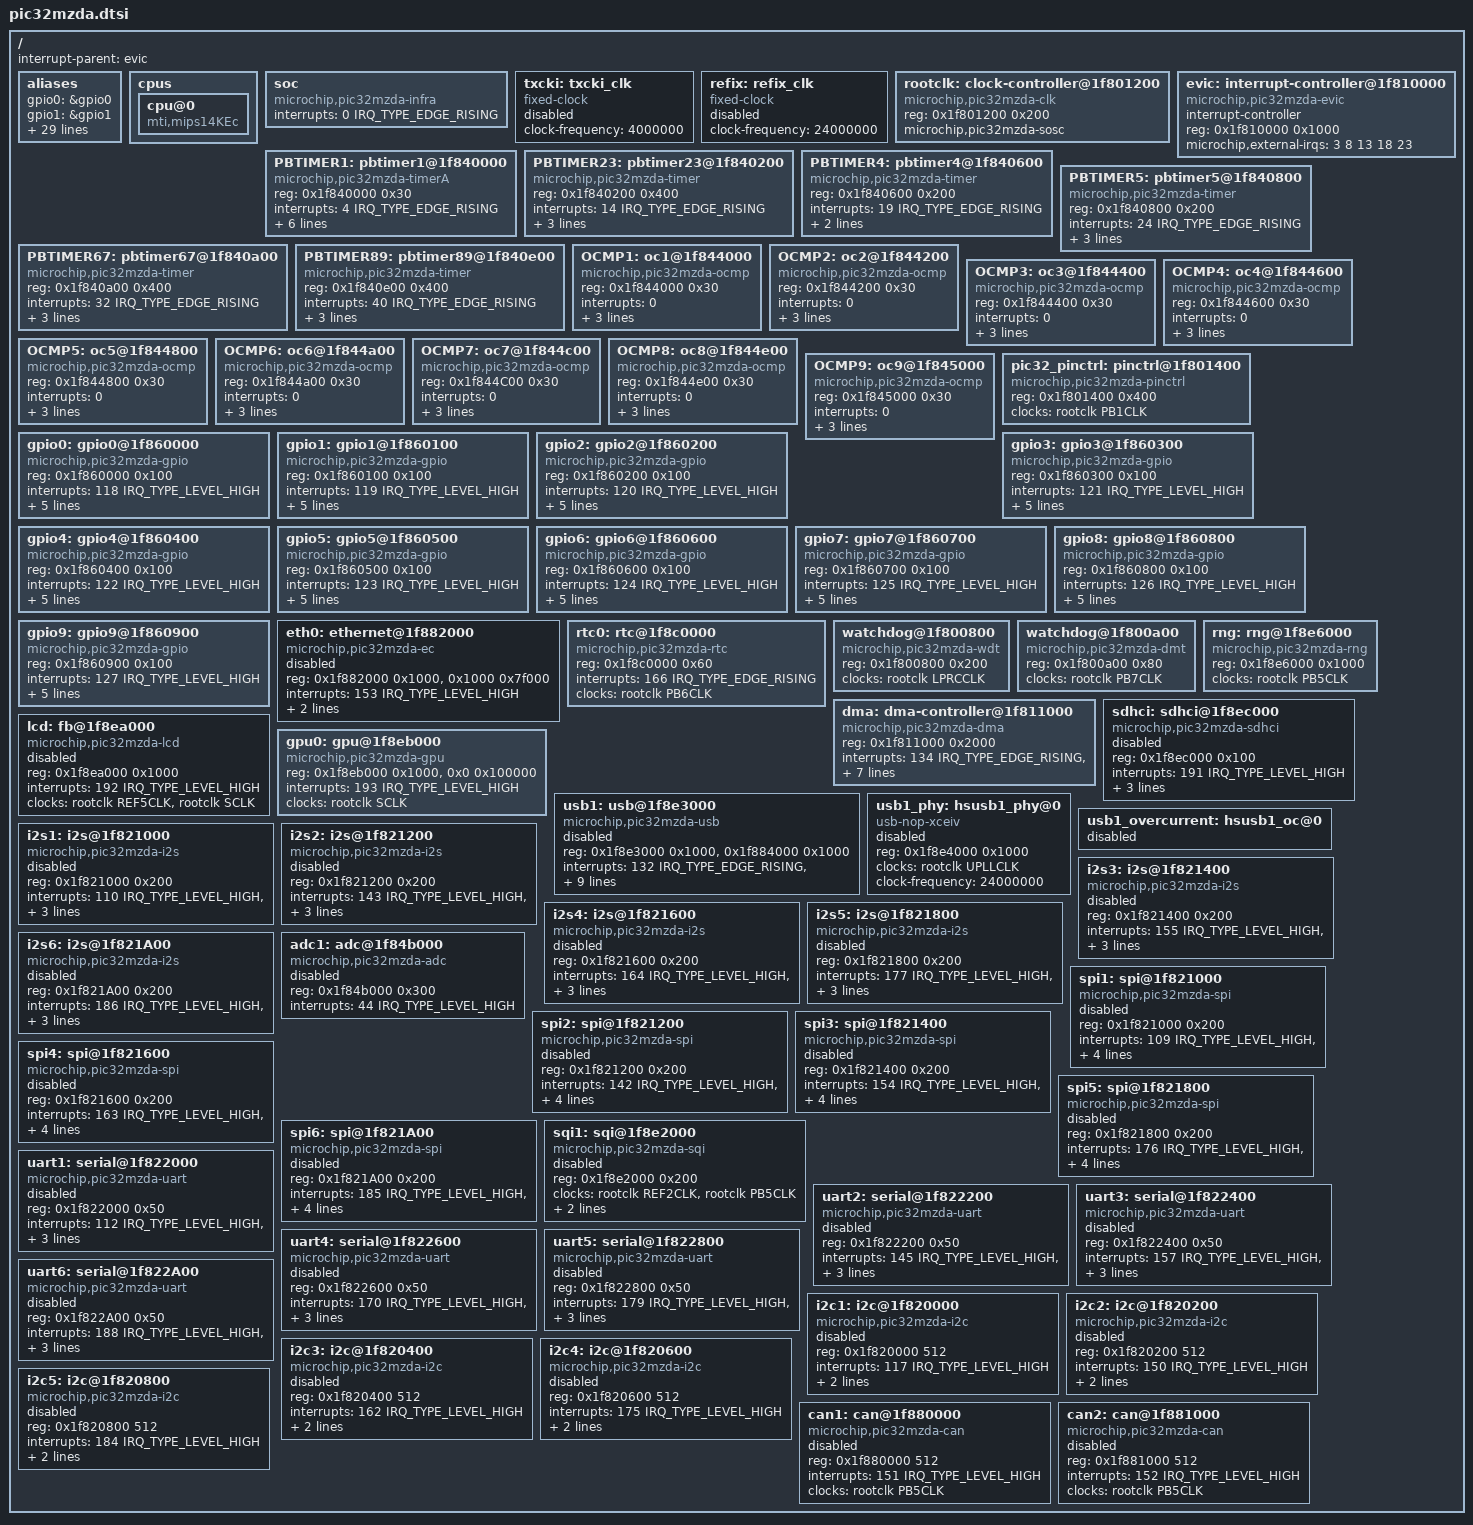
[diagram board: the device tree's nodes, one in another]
/*
 * Copyright (C) 2015 Microchip Technology Inc.  All rights reserved.
 *
 * This program is free software; you can redistribute it and/or modify
 * it under the terms of the GNU General Public License version 2 as
 * published by the Free Software Foundation.
 *
 */
#include <dt-bindings/clock/microchip,pic32-clock.h>
#include <dt-bindings/interrupt-controller/irq.h>

/ {
	#address-cells = <1>;
	#size-cells = <1>;
	interrupt-parent = <&evic>;

	aliases {
		gpio0 = &gpio0;
		gpio1 = &gpio1;
		gpio2 = &gpio2;
		gpio3 = &gpio3;
		gpio4 = &gpio4;
		gpio5 = &gpio5;
		gpio6 = &gpio6;
		gpio7 = &gpio7;
		gpio8 = &gpio8;
		gpio9 = &gpio9;
		serial0 = &uart1;
		serial1 = &uart2;
		serial2 = &uart3;
		serial3 = &uart4;
		serial4 = &uart5;
		serial5 = &uart6;
		i2s1 = &i2s1;
		i2s2 = &i2s2;
		i2s3 = &i2s3;
		i2s4 = &i2s4;
		i2s5 = &i2s5;
		i2s6 = &i2s6;
		spi1 = &spi1;
		spi2 = &spi2;
		spi3 = &spi3;
		spi4 = &spi4;
		spi5 = &spi5;
		spi6 = &spi6;
		spi7 = &sqi1;
		usb1 = &usb1;
		usb1_phy = &usb1_phy;
	};

	cpus {
		#address-cells = <1>;
		#size-cells = <0>;

		cpu@0 {
			compatible = "mti,mips14KEc";
			device_type = "cpu";
		};
	};

	soc {
		compatible = "microchip,pic32mzda-infra";
		interrupts = <0 IRQ_TYPE_EDGE_RISING>;
	};

	/* external clock input on TxCLKI pin */
	txcki: txcki_clk {
		#clock-cells = <0>;
		compatible = "fixed-clock";
		clock-frequency = <4000000>;
		status = "disabled";
	};

	/* external input on REFCLKIx pin */
	refix: refix_clk {
		#clock-cells = <0>;
		compatible = "fixed-clock";
		clock-frequency = <24000000>;
		status = "disabled";
	};

	rootclk: clock-controller@1f801200 {
		compatible = "microchip,pic32mzda-clk";
		reg = <0x1f801200 0x200>;
		#clock-cells = <1>;
		microchip,pic32mzda-sosc;
	};

	evic: interrupt-controller@1f810000 {
		compatible = "microchip,pic32mzda-evic";
		interrupt-controller;
		#interrupt-cells = <2>;
		reg = <0x1f810000 0x1000>;
		microchip,external-irqs = <3 8 13 18 23>;
	};

	/* 16-bit class-a timer */
	PBTIMER1: pbtimer1@1f840000 {
		#timer-cells = <0>;
		reg = <0x1f840000 0x30>;
		compatible = "microchip,pic32mzda-timerA";
		interrupts = <4 IRQ_TYPE_EDGE_RISING>;
		clocks = <&rootclk PB3CLK>, <&rootclk SOSCCLK>, <&rootclk LPRCCLK>;
		microchip,clock-indices = <0>, <1>, <5>;
		timer-id = <1>;
		microchip,timer-class-A;  /* class A timer */
		microchip,timer-version = <2>; /* v2 timer */
	};

	/* 32-bit class-b timer */
	PBTIMER23: pbtimer23@1f840200 {
		#timer-cells = <0>;
		compatible = "microchip,pic32mzda-timer";
		reg = <0x1f840200 0x400>;
		interrupts = <14 IRQ_TYPE_EDGE_RISING>;
		clocks = <&rootclk PB3CLK>, <&txcki>;
		timer-id = <2>;
		microchip,timer-32bit;	 /* class B, 32-bit combined timer */
	};

	/* 16-bit class-b timer */
	PBTIMER4: pbtimer4@1f840600 {
		#timer-cells = <0>;
		compatible = "microchip,pic32mzda-timer";
		reg = <0x1f840600 0x200>;
		interrupts = <19 IRQ_TYPE_EDGE_RISING>;
		clocks = <&rootclk PB3CLK>, <&txcki>;
		timer-id = <4>;
	};

	/* 16-bit class-b timer */
	PBTIMER5: pbtimer5@1f840800 {
		#timer-cells = <0>;
		compatible = "microchip,pic32mzda-timer";
		reg = <0x1f840800 0x200>;
		interrupts = <24 IRQ_TYPE_EDGE_RISING>;
		clocks = <&rootclk PB3CLK>, <&txcki>;
		timer-id = <5>;
		microchip,timer-adc; /* can trigger ADC on match */
	};

	/* 32-bit class-b timer */
	PBTIMER67: pbtimer67@1f840a00 {
		#timer-cells = <0>;
		compatible = "microchip,pic32mzda-timer";
		reg = <0x1f840a00 0x400>;
		interrupts = <32 IRQ_TYPE_EDGE_RISING>;
		clocks = <&rootclk PB3CLK>, <&txcki>;
		timer-id = <6>;
		microchip,timer-32bit;
	};

	/* 32-bit class-b timer */
	PBTIMER89: pbtimer89@1f840e00 {
		#timer-cells = <0>;
		compatible = "microchip,pic32mzda-timer";
		reg = <0x1f840e00 0x400>;
		interrupts = <40 IRQ_TYPE_EDGE_RISING>;
		clocks = <&rootclk PB3CLK>, <&txcki>;
		timer-id = <8>;
		microchip,timer-32bit;
	};

	/* 32-bit time-base and 32-bit compare */
	OCMP1: oc1@1f844000 {
		#oc-cells = <0>;
		compatible = "microchip,pic32mzda-ocmp";
		reg = <0x1f844000 0x30>;
		interrupts = <0>;
		oc-id = <1>;
		microchip,oc-32bit;
		microchip,oc-adc;
	};

	/* 16-bit time-base, hence 16-bit count comparision */
	OCMP2: oc2@1f844200 {
		#oc-cells = <0>;
		compatible = "microchip,pic32mzda-ocmp";
		reg = <0x1f844200 0x30>;
		interrupts = <0>;
		oc-id = <2>;
		microchip,oc-adc;
		microchip,oc-32bit;
	};

	OCMP3: oc3@1f844400 {
		#oc-cells = <0>;
		compatible = "microchip,pic32mzda-ocmp";
		reg = <0x1f844400 0x30>;
		interrupts = <0>;
		oc-id = <3>;
		microchip,oc-adc;
		microchip,oc-32bit;
	};

	OCMP4: oc4@1f844600 {
		#oc-cells = <0>;
		compatible = "microchip,pic32mzda-ocmp";
		reg = <0x1f844600 0x30>;
		interrupts = <0>;
		oc-id = <4>;
		microchip,oc-adc;
		microchip,oc-32bit;
	};

	OCMP5: oc5@1f844800 {
		#oc-cells = <0>;
		compatible = "microchip,pic32mzda-ocmp";
		reg = <0x1f844800 0x30>;
		interrupts = <0>;
		oc-id = <5>;
		microchip,oc-adc;
		microchip,oc-32bit;
	};

	OCMP6: oc6@1f844a00 {
		#oc-cells = <0>;
		compatible = "microchip,pic32mzda-ocmp";
		reg = <0x1f844a00 0x30>;
		interrupts = <0>;
		oc-id = <2>;
		microchip,oc-adc;
		microchip,oc-32bit;
	};

	OCMP7: oc7@1f844c00 {
		#oc-cells = <0>;
		compatible = "microchip,pic32mzda-ocmp";
		reg = <0x1f844C00 0x30>;
		interrupts = <0>;
		oc-id = <7>;
		microchip,oc-adc;
		microchip,oc-32bit;
	};

	OCMP8: oc8@1f844e00 {
		#oc-cells = <0>;
		compatible = "microchip,pic32mzda-ocmp";
		reg = <0x1f844e00 0x30>;
		interrupts = <0>;
		oc-id = <8>;
		microchip,oc-adc;
		microchip,oc-32bit;
	};

	OCMP9: oc9@1f845000 {
		#oc-cells = <0>;
		compatible = "microchip,pic32mzda-ocmp";
		reg = <0x1f845000 0x30>;
		interrupts = <0>;
		oc-id = <9>;
		microchip,oc-adc;
		microchip,oc-32bit;
	};

	pic32_pinctrl: pinctrl@1f801400{
		#address-cells = <1>;
		#size-cells = <1>;
		compatible = "microchip,pic32mzda-pinctrl";
		reg = <0x1f801400 0x400>;
		clocks = <&rootclk PB1CLK>;
	};

	/* PORTA */
	gpio0: gpio0@1f860000 {
		compatible = "microchip,pic32mzda-gpio";
		reg = <0x1f860000 0x100>;
		interrupts = <118 IRQ_TYPE_LEVEL_HIGH>;
		#gpio-cells = <2>;
		gpio-controller;
		interrupt-controller;
		#interrupt-cells = <2>;
		clocks = <&rootclk PB4CLK>;
		microchip,gpio-bank = <0>;
		gpio-ranges = <&pic32_pinctrl 0 0 16>;
	};

	/* PORTB */
	gpio1: gpio1@1f860100 {
		compatible = "microchip,pic32mzda-gpio";
		reg = <0x1f860100 0x100>;
		interrupts = <119 IRQ_TYPE_LEVEL_HIGH>;
		#gpio-cells = <2>;
		gpio-controller;
		interrupt-controller;
		#interrupt-cells = <2>;
		clocks = <&rootclk PB4CLK>;
		microchip,gpio-bank = <1>;
		gpio-ranges = <&pic32_pinctrl 0 16 16>;
	};

	/* PORTC */
	gpio2: gpio2@1f860200 {
		compatible = "microchip,pic32mzda-gpio";
		reg = <0x1f860200 0x100>;
		interrupts = <120 IRQ_TYPE_LEVEL_HIGH>;
		#gpio-cells = <2>;
		gpio-controller;
		interrupt-controller;
		#interrupt-cells = <2>;
		clocks = <&rootclk PB4CLK>;
		microchip,gpio-bank = <2>;
		gpio-ranges = <&pic32_pinctrl 0 32 16>;
	};

	/* PORTD */
	gpio3: gpio3@1f860300 {
		compatible = "microchip,pic32mzda-gpio";
		reg = <0x1f860300 0x100>;
		interrupts = <121 IRQ_TYPE_LEVEL_HIGH>;
		#gpio-cells = <2>;
		gpio-controller;
		interrupt-controller;
		#interrupt-cells = <2>;
		clocks = <&rootclk PB4CLK>;
		microchip,gpio-bank = <3>;
		gpio-ranges = <&pic32_pinctrl 0 48 16>;
	};

	/* PORTE */
	gpio4: gpio4@1f860400 {
		compatible = "microchip,pic32mzda-gpio";
		reg = <0x1f860400 0x100>;
		interrupts = <122 IRQ_TYPE_LEVEL_HIGH>;
		#gpio-cells = <2>;
		gpio-controller;
		interrupt-controller;
		#interrupt-cells = <2>;
		clocks = <&rootclk PB4CLK>;
		microchip,gpio-bank = <4>;
		gpio-ranges = <&pic32_pinctrl 0 64 16>;
	};

	/* PORTF */
	gpio5: gpio5@1f860500 {
		compatible = "microchip,pic32mzda-gpio";
		reg = <0x1f860500 0x100>;
		interrupts = <123 IRQ_TYPE_LEVEL_HIGH>;
		#gpio-cells = <2>;
		gpio-controller;
		interrupt-controller;
		#interrupt-cells = <2>;
		clocks = <&rootclk PB4CLK>;
		microchip,gpio-bank = <5>;
		gpio-ranges = <&pic32_pinctrl 0 80 16>;
	};

	/* PORTG */
	gpio6: gpio6@1f860600 {
		compatible = "microchip,pic32mzda-gpio";
		reg = <0x1f860600 0x100>;
		interrupts = <124 IRQ_TYPE_LEVEL_HIGH>;
		#gpio-cells = <2>;
		gpio-controller;
		interrupt-controller;
		#interrupt-cells = <2>;
		clocks = <&rootclk PB4CLK>;
		microchip,gpio-bank = <6>;
		gpio-ranges = <&pic32_pinctrl 0 96 16>;
	};

	/* PORTH */
	gpio7: gpio7@1f860700 {
		compatible = "microchip,pic32mzda-gpio";
		reg = <0x1f860700 0x100>;
		interrupts = <125 IRQ_TYPE_LEVEL_HIGH>;
		#gpio-cells = <2>;
		gpio-controller;
		interrupt-controller;
		#interrupt-cells = <2>;
		clocks = <&rootclk PB4CLK>;
		microchip,gpio-bank = <7>;
		gpio-ranges = <&pic32_pinctrl 0 112 16>;
	};

	/* PORTI does not exist */

	/* PORTJ */
	gpio8: gpio8@1f860800 {
		compatible = "microchip,pic32mzda-gpio";
		reg = <0x1f860800 0x100>;
		interrupts = <126 IRQ_TYPE_LEVEL_HIGH>;
		#gpio-cells = <2>;
		gpio-controller;
		interrupt-controller;
		#interrupt-cells = <2>;
		clocks = <&rootclk PB4CLK>;
		microchip,gpio-bank = <8>;
		gpio-ranges = <&pic32_pinctrl 0 128 16>;
	};

	/* PORTK */
	gpio9: gpio9@1f860900 {
		compatible = "microchip,pic32mzda-gpio";
		reg = <0x1f860900 0x100>;
		interrupts = <127 IRQ_TYPE_LEVEL_HIGH>;
		#gpio-cells = <2>;
		gpio-controller;
		interrupt-controller;
		#interrupt-cells = <2>;
		clocks = <&rootclk PB4CLK>;
		microchip,gpio-bank = <9>;
		gpio-ranges = <&pic32_pinctrl 0 144 16>;
	};

	eth0: ethernet@1f882000 {
		compatible = "microchip,pic32mzda-ec";
		reg = <0x1f882000 0x1000>, <0x1000 0x7f000>;
		reg-names = "regs", "mem";
		interrupts = <153 IRQ_TYPE_LEVEL_HIGH>;
		phy-mode = "rmii";
		clock-names = "eth_clk";
		clocks = <&rootclk PB5CLK>;
		status = "disabled";
	};

	rtc0: rtc@1f8c0000 {
		compatible = "microchip,pic32mzda-rtc";
		reg = <0x1f8c0000 0x60>;
		interrupts = <166 IRQ_TYPE_EDGE_RISING>;
		clocks = <&rootclk PB6CLK>;
	};

	watchdog@1f800800 {
		compatible = "microchip,pic32mzda-wdt";
		reg = <0x1f800800 0x200>;
		clocks = <&rootclk LPRCCLK>;
	};

	watchdog@1f800a00 {
		compatible = "microchip,pic32mzda-dmt";
		reg = <0x1f800a00 0x80>;
		clocks = <&rootclk PB7CLK>;
	};

	rng: rng@1f8e6000 {
		compatible = "microchip,pic32mzda-rng";
		reg = <0x1f8e6000 0x1000>;
		clocks = <&rootclk PB5CLK>;
	};

	dma: dma-controller@1f811000 {
		compatible = "microchip,pic32mzda-dma";
		reg = <0x1f811000 0x2000>;
		interrupts = <134 IRQ_TYPE_EDGE_RISING>,
			<135 IRQ_TYPE_EDGE_RISING>,
			<136 IRQ_TYPE_EDGE_RISING>,
			<137 IRQ_TYPE_EDGE_RISING>,
			<138 IRQ_TYPE_EDGE_RISING>,
			<139 IRQ_TYPE_EDGE_RISING>,
			<140 IRQ_TYPE_EDGE_RISING>,
			<141 IRQ_TYPE_EDGE_RISING>;
		#dma-cells = <1>;
	};

	sdhci: sdhci@1f8ec000 {
		compatible = "microchip,pic32mzda-sdhci";
		reg = <0x1f8ec000 0x100>;
		interrupts = <191 IRQ_TYPE_LEVEL_HIGH>;
		clocks = <&rootclk REF4CLK>, <&rootclk PB5CLK>;
		clock-names = "base_clk", "sys_clk";
		bus-width = <4>;
		cap-sd-highspeed;
		status = "disabled";
	};

	lcd: fb@1f8ea000 {
		compatible = "microchip,pic32mzda-lcd";
		reg = <0x1f8ea000 0x1000>;
		interrupts = <192 IRQ_TYPE_LEVEL_HIGH>;
		clocks = <&rootclk REF5CLK>, <&rootclk SCLK>;
		clock-names = "lcd_clk", "sys_clk";
		status = "disabled";
	};

	gpu0: gpu@1f8eb000 {
		compatible = "microchip,pic32mzda-gpu";
		reg = <0x1f8eb000 0x1000>, <0x0 0x100000>;
		reg-names = "gpu_base", "gpu_mem";
		interrupts = <193 IRQ_TYPE_LEVEL_HIGH>;
		interrupt-names = "gpu_irq";
		clocks = <&rootclk SCLK>;
		clock-names = "sys_clk";
	};

	usb1: usb@1f8e3000 {
		compatible = "microchip,pic32mzda-usb";
		reg = <0x1f8e3000 0x1000>,
		      <0x1f884000 0x1000>;
		reg-names = "mc", "usbcr";
		interrupts = <132 IRQ_TYPE_EDGE_RISING>,
			     <133 IRQ_TYPE_LEVEL_HIGH>;
		interrupt-names = "mc", "dma";
		dr_mode = "host";
		mentor,multipoint = <1>;
		mentor,num-eps = <8>;
		mentor,ram-bits = <11>;
		mentor,power = <500>;
		phys = <&usb1_phy>;
		clocks = <&rootclk PB5CLK>;
		clock-names = "usb_clk";
		usb_overcurrent=<&usb1_overcurrent>;
		status = "disabled";
	};

	usb1_phy: hsusb1_phy@0 {
		compatible = "usb-nop-xceiv";
		reg = <0x1f8e4000 0x1000>;
		clocks = <&rootclk UPLLCLK>;
		clock-names = "main_clk";
		clock-frequency = <24000000>;
		status = "disabled";
	};

	usb1_overcurrent: hsusb1_oc@0 {
		status = "disabled";
	};

	i2s1: i2s@1f821000 {
		compatible = "microchip,pic32mzda-i2s";
		reg = <0x1f821000 0x200>;
		interrupts = <110 IRQ_TYPE_LEVEL_HIGH>,
			<111 IRQ_TYPE_LEVEL_HIGH>;
		dmas = <&dma 134>, <&dma 135>;
		dma-names = "rx", "tx";
		clocks = <&rootclk PB2CLK>, <&rootclk REF1CLK>;
		clock-names = "mck0", "mck1";
		status = "disabled";
	};

	i2s2: i2s@1f821200 {
		compatible = "microchip,pic32mzda-i2s";
		reg = <0x1f821200 0x200>;
		interrupts = <143 IRQ_TYPE_LEVEL_HIGH>,
			<144 IRQ_TYPE_LEVEL_HIGH>;
		dmas = <&dma 136>, <&dma 137>;
		dma-names = "rx", "tx";
		clocks = <&rootclk PB2CLK>, <&rootclk REF1CLK>;
		clock-names = "mck0", "mck1";
		status = "disabled";
	};

	i2s3: i2s@1f821400 {
		compatible = "microchip,pic32mzda-i2s";
		reg = <0x1f821400 0x200>;
		interrupts = <155 IRQ_TYPE_LEVEL_HIGH>,
			<156 IRQ_TYPE_LEVEL_HIGH>;
		dmas = <&dma 138>, <&dma 139>;
		dma-names = "rx", "tx";
		clocks = <&rootclk PB2CLK>, <&rootclk REF1CLK>;
		clock-names = "mck0", "mck1";
		status = "disabled";
	};

	i2s4: i2s@1f821600 {
		compatible = "microchip,pic32mzda-i2s";
		reg = <0x1f821600 0x200>;
		interrupts = <164 IRQ_TYPE_LEVEL_HIGH>,
			<165 IRQ_TYPE_LEVEL_HIGH>;
		dmas = <&dma 140>, <&dma 141>;
		dma-names = "rx", "tx";
		clocks = <&rootclk PB2CLK>, <&rootclk REF1CLK>;
		clock-names = "mck0", "mck1";
		status = "disabled";
	};

	i2s5: i2s@1f821800 {
		compatible = "microchip,pic32mzda-i2s";
		reg = <0x1f821800 0x200>;
		interrupts = <177 IRQ_TYPE_LEVEL_HIGH>,
			<178 IRQ_TYPE_LEVEL_HIGH>;
		dmas = <&dma 134>, <&dma 135>;
		dma-names = "rx", "tx";
		clocks = <&rootclk PB2CLK>, <&rootclk REF1CLK>;
		clock-names = "mck0", "mck1";
		status = "disabled";
	};

	i2s6: i2s@1f821A00 {
		compatible = "microchip,pic32mzda-i2s";
		reg = <0x1f821A00 0x200>;
		interrupts = <186 IRQ_TYPE_LEVEL_HIGH>,
			<187 IRQ_TYPE_LEVEL_HIGH>;
		dmas = <&dma 136>, <&dma 137>;
		dma-names = "rx", "tx";
		clocks = <&rootclk PB2CLK>, <&rootclk REF1CLK>;
		clock-names = "mck0", "mck1";
		status = "disabled";
	};

	adc1: adc@1f84b000 {
		compatible = "microchip,pic32mzda-adc";
		reg = <0x1f84b000 0x300>;
		interrupts = <44 IRQ_TYPE_LEVEL_HIGH>;
		status = "disabled";
	};

	spi1: spi@1f821000 {
		#address-cells = <1>;
		#size-cells = <0>;
		compatible = "microchip,pic32mzda-spi";
		reg = <0x1f821000 0x200>;
		interrupts = <109 IRQ_TYPE_LEVEL_HIGH>,
			<110 IRQ_TYPE_LEVEL_HIGH>,
			<111 IRQ_TYPE_LEVEL_HIGH>;
		interrupt-names = "fault", "rx", "tx";
		clocks = <&rootclk PB2CLK>;
		clock-names = "mck0";
		dmas = <&dma 134>, <&dma 135>;
		dma-names = "spi-rx", "spi-tx";
		status = "disabled";
	};

	spi2: spi@1f821200 {
		#address-cells = <1>;
		#size-cells = <0>;
		compatible = "microchip,pic32mzda-spi";
		reg = <0x1f821200 0x200>;
		interrupts = <142 IRQ_TYPE_LEVEL_HIGH>,
			<143 IRQ_TYPE_LEVEL_HIGH>,
			<144 IRQ_TYPE_LEVEL_HIGH>;
		interrupt-names = "fault", "rx", "tx";
		clocks = <&rootclk PB2CLK>;
		clock-names = "mck0";
		dmas = <&dma 136>, <&dma 137>;
		dma-names = "spi-rx", "spi-tx";
		status = "disabled";
	};

	spi3: spi@1f821400 {
		#address-cells = <1>;
		#size-cells = <0>;
		compatible = "microchip,pic32mzda-spi";
		reg = <0x1f821400 0x200>;
		interrupts = <154 IRQ_TYPE_LEVEL_HIGH>,
			<155 IRQ_TYPE_LEVEL_HIGH>,
			<156 IRQ_TYPE_LEVEL_HIGH>;
		interrupt-names = "fault", "rx", "tx";
		clocks = <&rootclk PB2CLK>;
		clock-names = "mck0";
		dmas = <&dma 138>, <&dma 139>;
		dma-names = "spi-rx", "spi-tx";
		status = "disabled";
	};

	spi4: spi@1f821600 {
		#address-cells = <1>;
		#size-cells = <0>;
		compatible = "microchip,pic32mzda-spi";
		reg = <0x1f821600 0x200>;
		interrupts = <163 IRQ_TYPE_LEVEL_HIGH>,
			<164 IRQ_TYPE_LEVEL_HIGH>,
			<165 IRQ_TYPE_LEVEL_HIGH>;
		interrupt-names = "fault", "rx", "tx";
		clocks = <&rootclk PB2CLK>;
		clock-names = "mck0";
		dmas = <&dma 140>, <&dma 141>;
		dma-names = "spi-rx", "spi-tx";
		status = "disabled";
	};

	spi5: spi@1f821800 {
		#address-cells = <1>;
		#size-cells = <0>;
		compatible = "microchip,pic32mzda-spi";
		reg = <0x1f821800 0x200>;
		interrupts = <176 IRQ_TYPE_LEVEL_HIGH>,
			<177 IRQ_TYPE_LEVEL_HIGH>,
			<178 IRQ_TYPE_LEVEL_HIGH>;
		interrupt-names = "fault", "rx", "tx";
		clocks = <&rootclk PB2CLK>;
		clock-names = "mck0";
		dmas = <&dma 134>, <&dma 135>;
		dma-names = "spi-rx", "spi-tx";
		status = "disabled";
	};

	spi6: spi@1f821A00 {
		#address-cells = <1>;
		#size-cells = <0>;
		compatible = "microchip,pic32mzda-spi";
		reg = <0x1f821A00 0x200>;
		interrupts = <185 IRQ_TYPE_LEVEL_HIGH>,
			<186 IRQ_TYPE_LEVEL_HIGH>,
			<187 IRQ_TYPE_LEVEL_HIGH>;
		interrupt-names = "fault", "rx", "tx";
		clocks = <&rootclk PB2CLK>;
		clock-names = "mck0";
		dmas = <&dma 136>, <&dma 137>;
		dma-names = "spi-rx", "spi-tx";
		status = "disabled";
	};

	sqi1: sqi@1f8e2000 {
		#address-cells = <1>;
		#size-cells = <0>;
		compatible = "microchip,pic32mzda-sqi";
		reg = <0x1f8e2000 0x200>;
		clocks = <&rootclk REF2CLK>, <&rootclk PB5CLK>;
		clock-names = "spi_ck", "reg_ck";
		interrupt-parent = <&evic>;
		interrupts = <169 IRQ_TYPE_LEVEL_HIGH>;
		status = "disabled";
	};

	uart1: serial@1f822000 {
		compatible = "microchip,pic32mzda-uart";
		reg = <0x1f822000 0x50>;
		interrupts = <112 IRQ_TYPE_LEVEL_HIGH>,
			<113 IRQ_TYPE_LEVEL_HIGH>,
			<114 IRQ_TYPE_LEVEL_HIGH>;
		clocks = <&rootclk PB2CLK>;
		status = "disabled";
	};

	uart2: serial@1f822200 {
		compatible = "microchip,pic32mzda-uart";
		reg = <0x1f822200 0x50>;
		interrupts = <145 IRQ_TYPE_LEVEL_HIGH>,
			<146 IRQ_TYPE_LEVEL_HIGH>,
			<147 IRQ_TYPE_LEVEL_HIGH>;
		clocks = <&rootclk PB2CLK>;
		status = "disabled";
	};

	uart3: serial@1f822400 {
		compatible = "microchip,pic32mzda-uart";
		reg = <0x1f822400 0x50>;
		interrupts = <157 IRQ_TYPE_LEVEL_HIGH>,
			<158 IRQ_TYPE_LEVEL_HIGH>,
			<159 IRQ_TYPE_LEVEL_HIGH>;
		clocks = <&rootclk PB2CLK>;
		status = "disabled";
	};

	uart4: serial@1f822600 {
		compatible = "microchip,pic32mzda-uart";
		reg = <0x1f822600 0x50>;
		interrupts = <170 IRQ_TYPE_LEVEL_HIGH>,
			<171 IRQ_TYPE_LEVEL_HIGH>,
			<172 IRQ_TYPE_LEVEL_HIGH>;
		clocks = <&rootclk PB2CLK>;
		status = "disabled";
	};

	uart5: serial@1f822800 {
		compatible = "microchip,pic32mzda-uart";
		reg = <0x1f822800 0x50>;
		interrupts = <179 IRQ_TYPE_LEVEL_HIGH>,
			<180 IRQ_TYPE_LEVEL_HIGH>,
			<181 IRQ_TYPE_LEVEL_HIGH>;
		clocks = <&rootclk PB2CLK>;
		status = "disabled";
	};

	uart6: serial@1f822A00 {
		compatible = "microchip,pic32mzda-uart";
		reg = <0x1f822A00 0x50>;
		interrupts = <188 IRQ_TYPE_LEVEL_HIGH>,
			<189 IRQ_TYPE_LEVEL_HIGH>,
			<190 IRQ_TYPE_LEVEL_HIGH>;
		clocks = <&rootclk PB2CLK>;
		status = "disabled";
	};

	i2c1: i2c@1f820000 {
		compatible = "microchip,pic32mzda-i2c";
		reg = <0x1f820000 512>;
		interrupts = <117 IRQ_TYPE_LEVEL_HIGH>;
		clock-frequency = <100000>;
		clocks = <&rootclk PB2CLK>;
		status = "disabled";
	};

	i2c2: i2c@1f820200 {
		compatible = "microchip,pic32mzda-i2c";
		reg = <0x1f820200 512>;
		interrupts = <150 IRQ_TYPE_LEVEL_HIGH>;
		clock-frequency = <100000>;
		clocks = <&rootclk PB2CLK>;
		status = "disabled";
	};

	i2c3: i2c@1f820400 {
		compatible = "microchip,pic32mzda-i2c";
		reg = <0x1f820400 512>;
		interrupts = <162 IRQ_TYPE_LEVEL_HIGH>;
		clock-frequency = <100000>;
		clocks = <&rootclk PB2CLK>;
		status = "disabled";
	};

	i2c4: i2c@1f820600 {
		compatible = "microchip,pic32mzda-i2c";
		reg = <0x1f820600 512>;
		interrupts = <175 IRQ_TYPE_LEVEL_HIGH>;
		clock-frequency = <100000>;
		clocks = <&rootclk PB2CLK>;
		status = "disabled";
	};

	i2c5: i2c@1f820800 {
		compatible = "microchip,pic32mzda-i2c";
		reg = <0x1f820800 512>;
		interrupts = <184 IRQ_TYPE_LEVEL_HIGH>;
		clock-frequency = <100000>;
		clocks = <&rootclk PB2CLK>;
		status = "disabled";
	};

	can1: can@1f880000 {
		compatible = "microchip,pic32mzda-can";
		reg = <0x1f880000 512>;
		interrupts = <151 IRQ_TYPE_LEVEL_HIGH>;
		clocks = <&rootclk PB5CLK>;
		clock-names = "can_clk";
		status = "disabled";
	};

	can2: can@1f881000 {
		compatible = "microchip,pic32mzda-can";
		reg = <0x1f881000 512>;
		interrupts = <152 IRQ_TYPE_LEVEL_HIGH>;
		clocks = <&rootclk PB5CLK>;
		clock-names = "can_clk";
		status = "disabled";
	};
};
